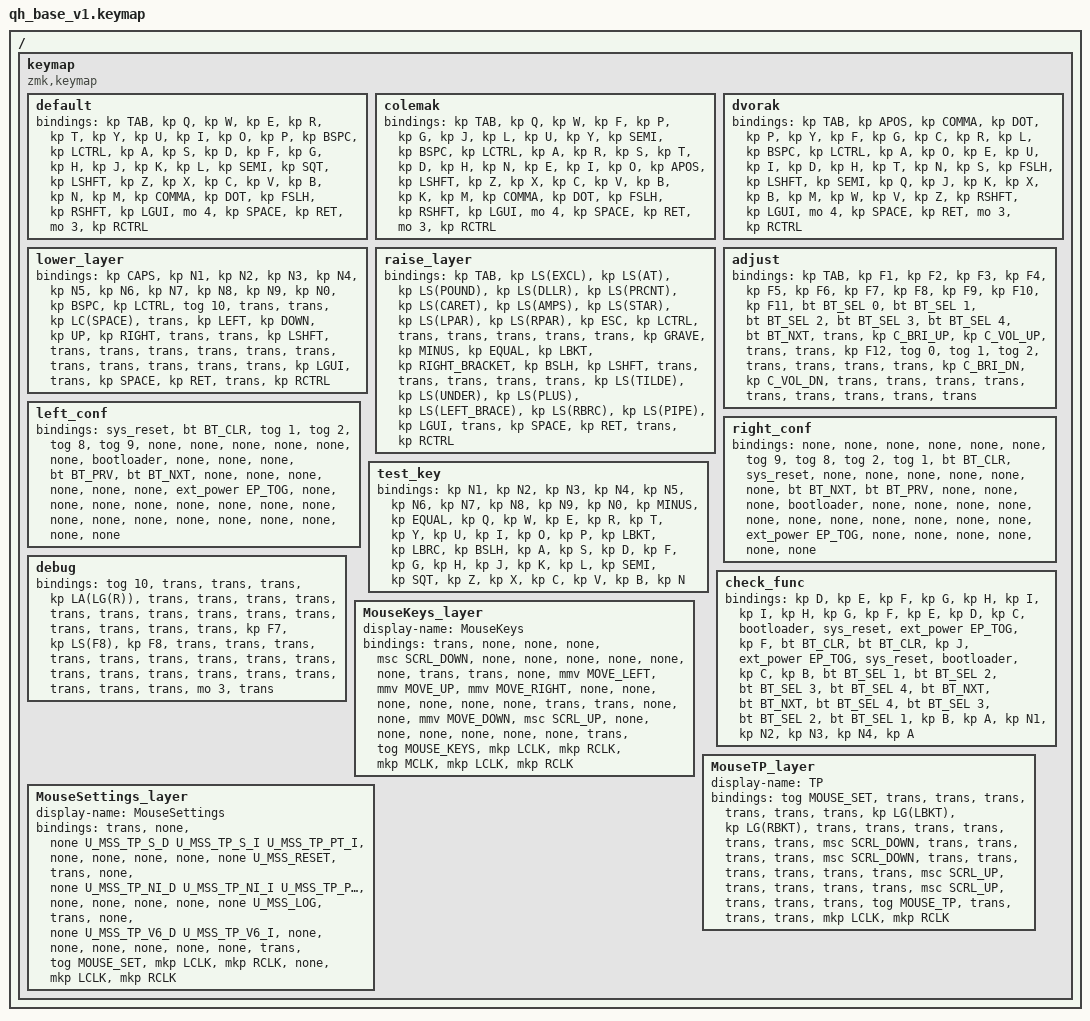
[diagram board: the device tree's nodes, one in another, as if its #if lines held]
/*
 * Copyright (c) 2020 The ZMK Contributors
 *
 * SPDX-License-Identifier: MIT
 */

// Define layer numbers
#define BASE 0
#define BASE_COLEMAK 1
#define BASE_DVORAK 2
#define LOWER 3
#define RAISE 4
#define ADJUST 5
#define LEFT_CONF 6
#define RIGHT_CONF 7
#define TEST_KEY 8
#define CHECK_FUNC 9
#define DEBUG 10
#define MOUSE_KEYS 11
#define MOUSE_TP 12
#define MOUSE_SET 13


// ZMK includes
#include <behaviors.dtsi>
#include <dt-bindings/zmk/keys.h>
#include <dt-bindings/zmk/bt.h>
#include <dt-bindings/zmk/rgb.h>
#include <dt-bindings/zmk/ext_power.h>


// Personal includes
#ifdef HAS_MOUSE_KEYS
     #include "includes/mouse_keys.dtsi"
#endif

#ifdef HAS_MOUSE_TP
     #include "includes/mouse_tp.dtsi"
#endif

// #include "includes/custom_keycodes.dtsi"
// #include "includes/settings.dtsi"
//#include "includes/settings_pd.dtsi"
// #include "includes/conditional_layers.dtsi"
// #include "includes/macros.dtsi"
// #include "includes/combos.dtsi"
// #include "includes/behaviours_homerow_mods.dtsi"
// #include "includes/behaviours_mod_morph.dtsi"
// #include "includes/behaviours_other.dtsi"

#include "includes/qh_conditional_layers_v1.dtsi"
#include "includes/qh_combos_v1.dtsi"

/ {

  keymap {
    compatible = "zmk,keymap";

            default {
            bindings = <
&kp TAB    &kp Q  &kp W  &kp E     &kp R  &kp T      &kp Y    &kp U  &kp I      &kp O    &kp P     &kp BSPC
&kp LCTRL  &kp A  &kp S  &kp D     &kp F  &kp G      &kp H    &kp J  &kp K      &kp L    &kp SEMI  &kp SQT
&kp LSHFT  &kp Z  &kp X  &kp C     &kp V  &kp B      &kp N    &kp M  &kp COMMA  &kp DOT  &kp FSLH  &kp RSHFT
                         &kp LGUI  &mo 4  &kp SPACE  &kp RET  &mo 3  &kp RCTRL
            >;
        };

        colemak {
            bindings = <
&kp TAB    &kp Q  &kp W  &kp F     &kp P  &kp G      &kp J    &kp L  &kp U      &kp Y    &kp SEMI  &kp BSPC
&kp LCTRL  &kp A  &kp R  &kp S     &kp T  &kp D      &kp H    &kp N  &kp E      &kp I    &kp O     &kp APOS
&kp LSHFT  &kp Z  &kp X  &kp C     &kp V  &kp B      &kp K    &kp M  &kp COMMA  &kp DOT  &kp FSLH  &kp RSHFT
                         &kp LGUI  &mo 4  &kp SPACE  &kp RET  &mo 3  &kp RCTRL
            >;
        };

        dvorak {
            bindings = <
&kp TAB    &kp APOS  &kp COMMA  &kp DOT   &kp P  &kp Y      &kp F    &kp G  &kp C      &kp R  &kp L  &kp BSPC
&kp LCTRL  &kp A     &kp O      &kp E     &kp U  &kp I      &kp D    &kp H  &kp T      &kp N  &kp S  &kp FSLH
&kp LSHFT  &kp SEMI  &kp Q      &kp J     &kp K  &kp X      &kp B    &kp M  &kp W      &kp V  &kp Z  &kp RSHFT
                                &kp LGUI  &mo 4  &kp SPACE  &kp RET  &mo 3  &kp RCTRL
            >;
        };

        lower_layer {
            bindings = <
&kp CAPS   &kp N1   &kp N2  &kp N3    &kp N4         &kp N5     &kp N6    &kp N7    &kp N8     &kp N9     &kp N0  &kp BSPC
&kp LCTRL  &tog 10  &trans  &trans    &kp LC(SPACE)  &trans     &kp LEFT  &kp DOWN  &kp UP     &kp RIGHT  &trans  &trans
&kp LSHFT  &trans   &trans  &trans    &trans         &trans     &trans    &trans    &trans     &trans     &trans  &trans
                            &kp LGUI  &trans         &kp SPACE  &kp RET   &trans    &kp RCTRL
            >;
        };

        raise_layer {
            bindings = <
&kp TAB    &kp LS(EXCL)  &kp LS(AT)  &kp LS(POUND)  &kp LS(DLLR)  &kp LS(PRCNT)  &kp LS(CARET)  &kp LS(AMPS)   &kp LS(STAR)  &kp LS(LPAR)        &kp LS(RPAR)       &kp ESC
&kp LCTRL  &trans        &trans      &trans         &trans        &trans         &kp GRAVE      &kp MINUS      &kp EQUAL     &kp LBKT            &kp RIGHT_BRACKET  &kp BSLH
&kp LSHFT  &trans        &trans      &trans         &trans        &trans         &kp LS(TILDE)  &kp LS(UNDER)  &kp LS(PLUS)  &kp LS(LEFT_BRACE)  &kp LS(RBRC)       &kp LS(PIPE)
                                     &kp LGUI       &trans        &kp SPACE      &kp RET        &trans         &kp RCTRL
            >;
        };

        adjust {
            bindings = <
&kp TAB       &kp F1        &kp F2        &kp F3        &kp F4        &kp F5      &kp F6  &kp F7        &kp F8        &kp F9  &kp F10  &kp F11
&bt BT_SEL 0  &bt BT_SEL 1  &bt BT_SEL 2  &bt BT_SEL 3  &bt BT_SEL 4  &bt BT_NXT  &trans  &kp C_BRI_UP  &kp C_VOL_UP  &trans  &trans   &kp F12
&tog 0        &tog 1        &tog 2        &trans        &trans        &trans      &trans  &kp C_BRI_DN  &kp C_VOL_DN  &trans  &trans   &trans
                                          &trans        &trans        &trans      &trans  &trans        &trans
            >;
        };

        left_conf {
            bindings = <
&sys_reset         &bt BT_CLR  &tog 1  &tog 2  &tog 8      &tog 9      &none  &none  &none  &none  &none  &none
&bootloader        &none       &none   &none   &bt BT_PRV  &bt BT_NXT  &none  &none  &none  &none  &none  &none
&ext_power EP_TOG  &none       &none   &none   &none       &none       &none  &none  &none  &none  &none  &none
                                       &none   &none       &none       &none  &none  &none
            >;
        };

        right_conf {
            bindings = <
&none  &none  &none  &none  &none  &none  &tog 9      &tog 8      &tog 2  &tog 1  &bt BT_CLR  &sys_reset
&none  &none  &none  &none  &none  &none  &bt BT_NXT  &bt BT_PRV  &none   &none   &none       &bootloader
&none  &none  &none  &none  &none  &none  &none       &none       &none   &none   &none       &ext_power EP_TOG
                     &none  &none  &none  &none       &none       &none
            >;
        };

        test_key {
            bindings = <
&kp N1    &kp N2  &kp N3  &kp N4  &kp N5  &kp N6  &kp N7  &kp N8  &kp N9  &kp N0  &kp MINUS  &kp EQUAL
&kp Q     &kp W   &kp E   &kp R   &kp T   &kp Y   &kp U   &kp I   &kp O   &kp P   &kp LBKT   &kp LBRC
&kp BSLH  &kp A   &kp S   &kp D   &kp F   &kp G   &kp H   &kp J   &kp K   &kp L   &kp SEMI   &kp SQT
                          &kp Z   &kp X   &kp C   &kp V   &kp B   &kp N
            >;
        };

        check_func {
            bindings = <
&kp D  &kp E         &kp F         &kp G              &kp H         &kp I       &kp I       &kp H         &kp G              &kp F         &kp E         &kp D
&kp C  &bootloader   &sys_reset    &ext_power EP_TOG  &kp F         &bt BT_CLR  &bt BT_CLR  &kp J         &ext_power EP_TOG  &sys_reset    &bootloader   &kp C
&kp B  &bt BT_SEL 1  &bt BT_SEL 2  &bt BT_SEL 3       &bt BT_SEL 4  &bt BT_NXT  &bt BT_NXT  &bt BT_SEL 4  &bt BT_SEL 3       &bt BT_SEL 2  &bt BT_SEL 1  &kp B
                                   &kp A              &kp N1        &kp N2      &kp N3      &kp N4        &kp A
            >;
        };

        debug {
            bindings = <
&tog 10  &trans  &trans  &trans  &kp LA(LG(R))  &trans  &trans  &trans  &trans      &trans  &trans  &trans
&trans   &trans  &trans  &trans  &trans         &trans  &trans  &kp F7  &kp LS(F8)  &kp F8  &trans  &trans
&trans   &trans  &trans  &trans  &trans         &trans  &trans  &trans  &trans      &trans  &trans  &trans
                         &trans  &trans         &trans  &trans  &mo 3   &trans
            >;
        };


#ifdef HAS_MOUSE_KEYS
    MouseKeys_layer {
      display-name = "MouseKeys";
      bindings = <
// ╭────────────────────────┬────────────────────────┬────────────────────────┬────────────────────────┬────────────────────────┬────────────────────────╮    ╭────────────────────────┬────────────────────────┬────────────────────────┬────────────────────────┬────────────────────────┬────────────────────────╮
     &trans                   &none                    &none                    &none                    &msc SCRL_DOWN           &none                         &none                    &none                    &none                    &none                    &none                     &trans
// ├────────────────────────┼────────────────────────┼────────────────────────┼────────────────────────┼────────────────────────┼────────────────────────┤    ├────────────────────────┼────────────────────────┼────────────────────────┼────────────────────────┼────────────────────────┼────────────────────────┤
     &trans                   &none                    &mmv MOVE_LEFT           &mmv MOVE_UP             &mmv MOVE_RIGHT          &none                         &none                    &none                    &none                    &none                    &none                     &trans
// ├────────────────────────┼────────────────────────┼────────────────────────┼────────────────────────┼────────────────────────┼────────────────────────┤    ├────────────────────────┼────────────────────────┼────────────────────────┼────────────────────────┼────────────────────────┼────────────────────────┤
     &trans                   &none                    &none                    &mmv MOVE_DOWN           &msc SCRL_UP             &none                         &none                    &none                    &none                    &none                    &none                     &trans
// ╰────────────────────────┴────────────────────────┴────────────────────────┴────────────────────────┼────────────────────────┼────────────────────────┤    ├────────────────────────┼────────────────────────┼────────────────────────┼────────────────────────┴────────────────────────┼────────────────────────╯
                                                                                &tog MOUSE_KEYS          &mkp LCLK                &mkp RCLK                     &mkp MCLK                &mkp LCLK                   &mkp RCLK
//                                                                            ╰────────────────────────┴────────────────────────┴────────────────────────╯    ╰────────────────────────┴────────────────────────┴────────────────────────╯
      >;
     //  sensor-bindings = <&inc_dec_kp C_BRI_DN C_BRI_UP &inc_dec_kp LEFT RIGHT>;
    };
#endif

#ifdef HAS_MOUSE_TP
    MouseTP_layer {
      display-name = "TP";
      bindings = <
// ╭────────────────────────┬────────────────────────┬────────────────────────┬────────────────────────┬────────────────────────┬────────────────────────╮    ╭────────────────────────┬────────────────────────┬────────────────────────┬────────────────────────┬────────────────────────┬────────────────────────╮
     &tog MOUSE_SET           &trans                   &trans                   &trans                   &trans                   &trans                        &trans                   &kp LG(LBKT)              &kp LG(RBKT)               &trans                   &trans                    &trans
// ├────────────────────────┼────────────────────────┼────────────────────────┼────────────────────────┼────────────────────────┼────────────────────────┤    ├────────────────────────┼────────────────────────┼────────────────────────┼────────────────────────┼────────────────────────┼────────────────────────┤
     &trans                   &trans                   &trans                   &msc SCRL_DOWN           &trans                   &trans                        &trans                   &trans                   &msc SCRL_DOWN           &trans                   &trans                    &trans
// ├────────────────────────┼────────────────────────┼────────────────────────┼────────────────────────┼────────────────────────┼────────────────────────┤    ├────────────────────────┼────────────────────────┼────────────────────────┼────────────────────────┼────────────────────────┼────────────────────────┤
     &trans                   &trans                   &trans                   &msc SCRL_UP             &trans                   &trans                        &trans                   &trans                   &msc SCRL_UP             &trans                   &trans                    &trans
// ╰────────────────────────┴────────────────────────┴────────────────────────┴────────────────────────┼────────────────────────┼────────────────────────┤    ├────────────────────────┼────────────────────────┼────────────────────────┼────────────────────────┴────────────────────────┼────────────────────────╯
                                                                                &tog MOUSE_TP            &trans                   &trans                        &trans                    &mkp LCLK               &mkp RCLK
//                                                                            ╰────────────────────────┴────────────────────────┴────────────────────────╯    ╰────────────────────────┴────────────────────────┴────────────────────────╯
      >;
     //  sensor-bindings = <&inc_dec_kp C_BRI_DN C_BRI_UP &inc_dec_kp LEFT RIGHT>;
    };

    MouseSettings_layer {
      display-name = "MouseSettings";
      bindings = <
// ╭────────────────────────┬────────────────────────┬────────────────────────┬────────────────────────┬────────────────────────┬────────────────────────╮    ╭────────────────────────┬────────────────────────┬────────────────────────┬────────────────────────┬────────────────────────┬────────────────────────╮
     &trans                   &none                    &none                    U_MSS_TP_S_D             U_MSS_TP_S_I             U_MSS_TP_PT_I                 &none                    &none                    &none                    &none                    &none                     U_MSS_RESET
// ├────────────────────────┼────────────────────────┼────────────────────────┼────────────────────────┼────────────────────────┼────────────────────────┤    ├────────────────────────┼────────────────────────┼────────────────────────┼────────────────────────┼────────────────────────┼────────────────────────┤
     &trans                   &none                    &none                    U_MSS_TP_NI_D            U_MSS_TP_NI_I            U_MSS_TP_PT_D                 &none                    &none                    &none                    &none                    &none                     U_MSS_LOG
// ├────────────────────────┼────────────────────────┼────────────────────────┼────────────────────────┼────────────────────────┼────────────────────────┤    ├────────────────────────┼────────────────────────┼────────────────────────┼────────────────────────┼────────────────────────┼────────────────────────┤
     &trans                   &none                    &none                    U_MSS_TP_V6_D            U_MSS_TP_V6_I            &none                         &none                    &none                    &none                    &none                    &none                     &trans
// ╰────────────────────────┴────────────────────────┴────────────────────────┴────────────────────────┼────────────────────────┼────────────────────────┤    ├────────────────────────┼────────────────────────┼────────────────────────┼────────────────────────┴────────────────────────┼────────────────────────╯
                                                                                &tog MOUSE_SET           &mkp LCLK                &mkp RCLK                     &none                    &mkp LCLK                &mkp RCLK
//                                                                            ╰────────────────────────┴────────────────────────┴────────────────────────╯    ╰────────────────────────┴────────────────────────┴────────────────────────╯
      >;
     //  sensor-bindings = <&inc_dec_kp C_BRI_DN C_BRI_UP &inc_dec_kp LEFT RIGHT>;
    };
#endif
  };

};
